# PIC32MX470F512L register map
Registers are 32-bit, access not given, reset 0x0 unless marked. A register's access mark holds for its fields unless they carry their own. Offsets are from the block's base; [hi:lo] are bit positions; {n}, {i} and the like mark numbered series; 'fields as' and 'values as' point back to an identical list.

## PORTG — PORTG peripheral
Base 0xBF886600
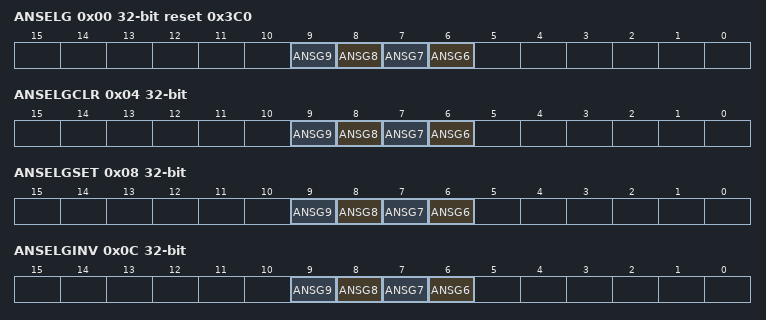
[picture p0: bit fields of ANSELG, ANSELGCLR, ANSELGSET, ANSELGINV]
0x00 ANSELG reset 0x3C0
  [n] ANSG{n} (n=6..9)
0x04 ANSELGCLR
  [n] ANSG{n} (n=6..9)
0x08 ANSELGSET
  [n] ANSG{n} (n=6..9)
0x0C ANSELGINV
  [n] ANSG{n} (n=6..9)
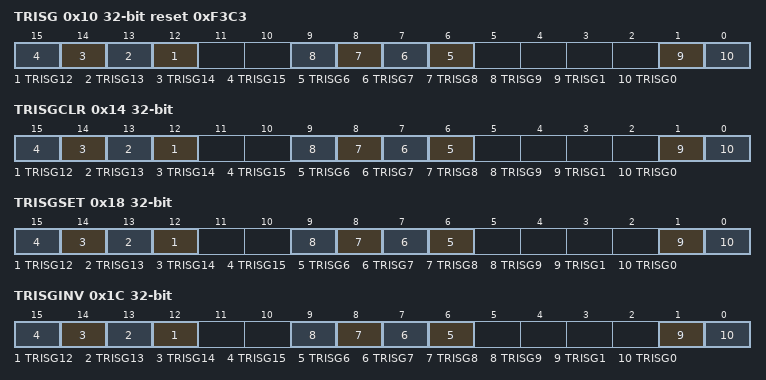
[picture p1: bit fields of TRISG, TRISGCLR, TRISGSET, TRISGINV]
0x10 TRISG reset 0xF3C3
  [n] TRISG{n} (n=12..15), [n] TRISG{n} (n=6..9), [1] TRISG1, [0] TRISG0
0x14 TRISGCLR
  fields as TRISG
0x18 TRISGSET
  fields as TRISG
0x1C TRISGINV
  fields as TRISG
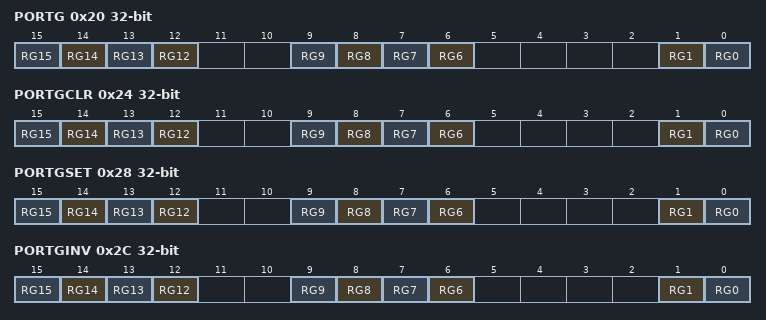
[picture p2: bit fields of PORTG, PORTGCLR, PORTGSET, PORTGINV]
0x20 PORTG
  [n] RG{n} (n=12..15), [n] RG{n} (n=6..9), [1] RG1, [0] RG0
0x24 PORTGCLR
  [n] RG{n} (n=12..15), [n] RG{n} (n=6..9), [1] RG1, [0] RG0
0x28 PORTGSET
  [n] RG{n} (n=12..15), [n] RG{n} (n=6..9), [1] RG1, [0] RG0
0x2C PORTGINV
  [n] RG{n} (n=12..15), [n] RG{n} (n=6..9), [1] RG1, [0] RG0
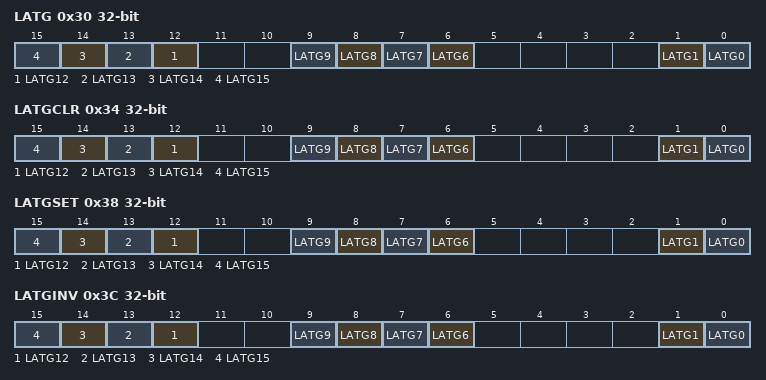
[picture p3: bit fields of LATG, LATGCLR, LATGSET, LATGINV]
0x30 LATG
  [n] LATG{n} (n=12..15), [n] LATG{n} (n=6..9), [1] LATG1, [0] LATG0
0x34 LATGCLR
  [n] LATG{n} (n=12..15), [n] LATG{n} (n=6..9), [1] LATG1, [0] LATG0
0x38 LATGSET
  [n] LATG{n} (n=12..15), [n] LATG{n} (n=6..9), [1] LATG1, [0] LATG0
0x3C LATGINV
  [n] LATG{n} (n=12..15), [n] LATG{n} (n=6..9), [1] LATG1, [0] LATG0
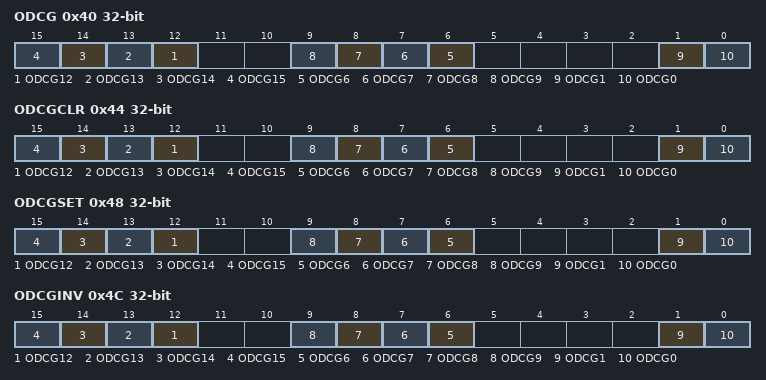
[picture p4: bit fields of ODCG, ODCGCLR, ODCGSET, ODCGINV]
0x40 ODCG
  [n] ODCG{n} (n=12..15), [n] ODCG{n} (n=6..9), [1] ODCG1, [0] ODCG0
0x44 ODCGCLR
  [n] ODCG{n} (n=12..15), [n] ODCG{n} (n=6..9), [1] ODCG1, [0] ODCG0
0x48 ODCGSET
  [n] ODCG{n} (n=12..15), [n] ODCG{n} (n=6..9), [1] ODCG1, [0] ODCG0
0x4C ODCGINV
  [n] ODCG{n} (n=12..15), [n] ODCG{n} (n=6..9), [1] ODCG1, [0] ODCG0
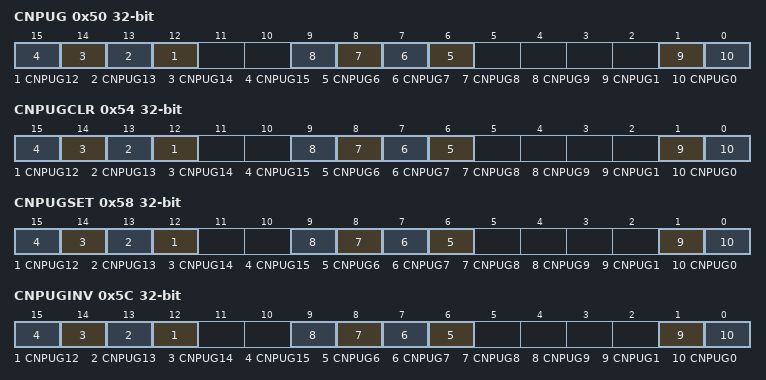
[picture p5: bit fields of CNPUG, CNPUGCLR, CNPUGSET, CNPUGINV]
0x50 CNPUG
  [n] CNPUG{n} (n=12..15), [n] CNPUG{n} (n=6..9), [1] CNPUG1, [0] CNPUG0
0x54 CNPUGCLR
  fields as CNPUG
0x58 CNPUGSET
  fields as CNPUG
0x5C CNPUGINV
  fields as CNPUG
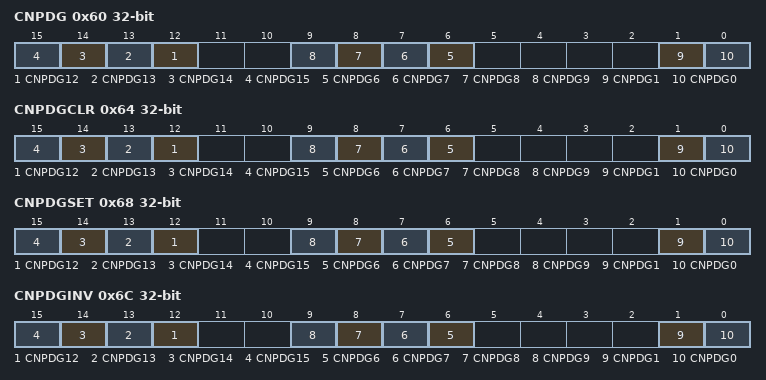
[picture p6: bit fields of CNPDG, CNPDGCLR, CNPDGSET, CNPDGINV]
0x60 CNPDG
  [n] CNPDG{n} (n=12..15), [n] CNPDG{n} (n=6..9), [1] CNPDG1, [0] CNPDG0
0x64 CNPDGCLR
  fields as CNPDG
0x68 CNPDGSET
  fields as CNPDG
0x6C CNPDGINV
  fields as CNPDG
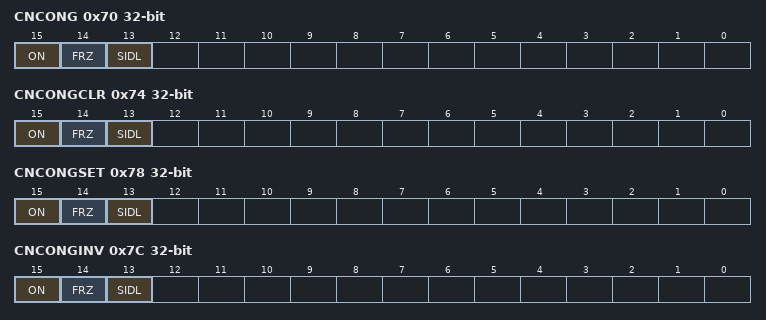
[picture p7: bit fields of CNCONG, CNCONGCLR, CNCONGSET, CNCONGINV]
0x70 CNCONG
  [15] ON, [14] FRZ, [13] SIDL
0x74 CNCONGCLR
  [15] ON, [14] FRZ, [13] SIDL
0x78 CNCONGSET
  [15] ON, [14] FRZ, [13] SIDL
0x7C CNCONGINV
  [15] ON, [14] FRZ, [13] SIDL
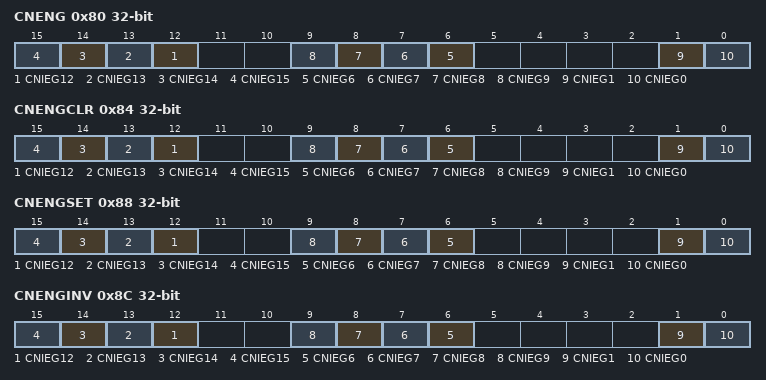
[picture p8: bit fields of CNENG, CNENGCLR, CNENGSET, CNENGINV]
0x80 CNENG
  [n] CNIEG{n} (n=12..15), [n] CNIEG{n} (n=6..9), [1] CNIEG1, [0] CNIEG0
0x84 CNENGCLR
  fields as CNENG
0x88 CNENGSET
  fields as CNENG
0x8C CNENGINV
  fields as CNENG
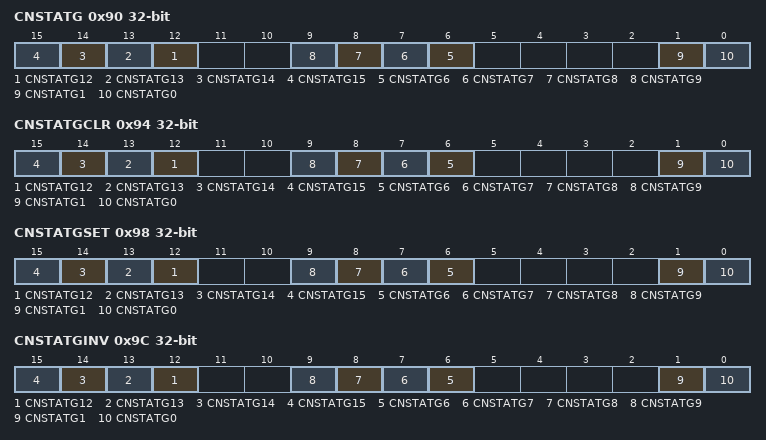
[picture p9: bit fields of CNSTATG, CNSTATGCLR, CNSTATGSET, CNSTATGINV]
0x90 CNSTATG
  [n] CNSTATG{n} (n=12..15), [n] CNSTATG{n} (n=6..9), [1] CNSTATG1, [0] CNSTATG0
0x94 CNSTATGCLR
  fields as CNSTATG
0x98 CNSTATGSET
  fields as CNSTATG
0x9C CNSTATGINV
  fields as CNSTATG

## WDT — WDT peripheral
Base 0xBF800000
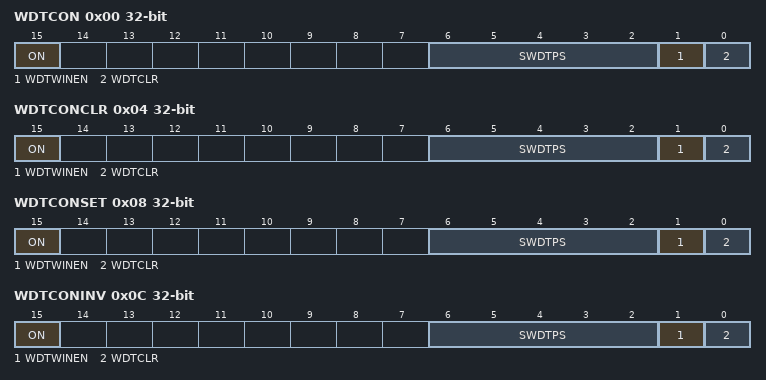
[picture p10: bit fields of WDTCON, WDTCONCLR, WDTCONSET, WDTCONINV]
0x00 WDTCON
  [15] ON, [6:2] SWDTPS, [1] WDTWINEN, [0] WDTCLR
0x04 WDTCONCLR
  [15] ON, [6:2] SWDTPS, [1] WDTWINEN, [0] WDTCLR
0x08 WDTCONSET
  [15] ON, [6:2] SWDTPS, [1] WDTWINEN, [0] WDTCLR
0x0C WDTCONINV
  [15] ON, [6:2] SWDTPS, [1] WDTWINEN, [0] WDTCLR

## RTCC — RTCC peripheral
Base 0xBF800200
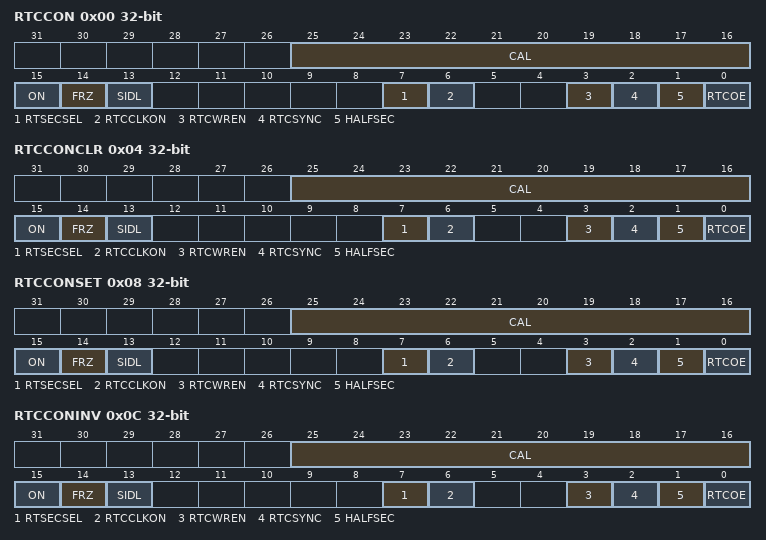
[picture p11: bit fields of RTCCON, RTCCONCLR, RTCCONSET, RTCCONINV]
0x00 RTCCON
  [25:16] CAL, [15] ON, [14] FRZ, [13] SIDL, [7] RTSECSEL, [6] RTCCLKON, [3] RTCWREN, [2] RTCSYNC, [1] HALFSEC, [0] RTCOE
0x04 RTCCONCLR
  fields as RTCCON
0x08 RTCCONSET
  fields as RTCCON
0x0C RTCCONINV
  fields as RTCCON
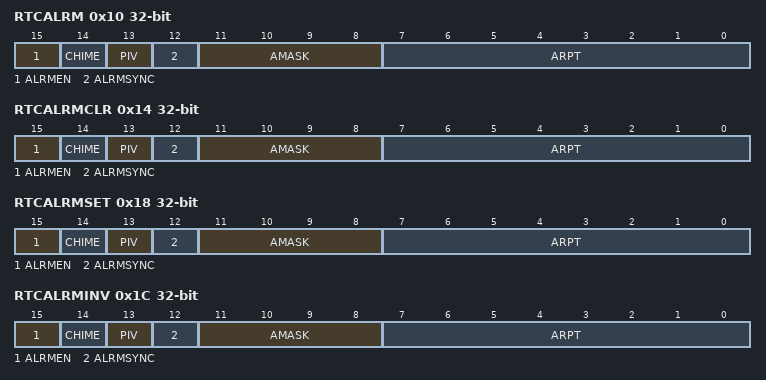
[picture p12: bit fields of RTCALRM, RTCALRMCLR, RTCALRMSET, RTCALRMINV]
0x10 RTCALRM
  [15] ALRMEN, [14] CHIME, [13] PIV, [12] ALRMSYNC, [11:8] AMASK, [7:0] ARPT
0x14 RTCALRMCLR
  fields as RTCALRM
0x18 RTCALRMSET
  fields as RTCALRM
0x1C RTCALRMINV
  fields as RTCALRM
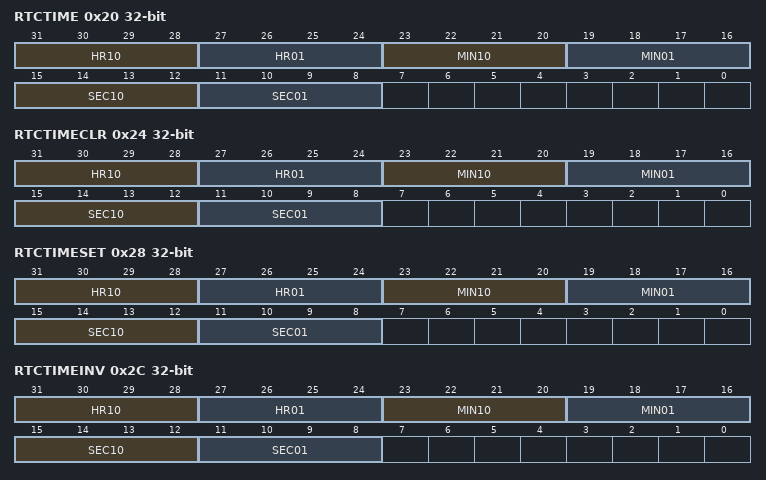
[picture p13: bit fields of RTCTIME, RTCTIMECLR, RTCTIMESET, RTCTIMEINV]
0x20 RTCTIME
  [31:28] HR10, [27:24] HR01, [23:20] MIN10, [19:16] MIN01, [15:12] SEC10, [11:8] SEC01
0x24 RTCTIMECLR
  fields as RTCTIME
0x28 RTCTIMESET
  fields as RTCTIME
0x2C RTCTIMEINV
  fields as RTCTIME
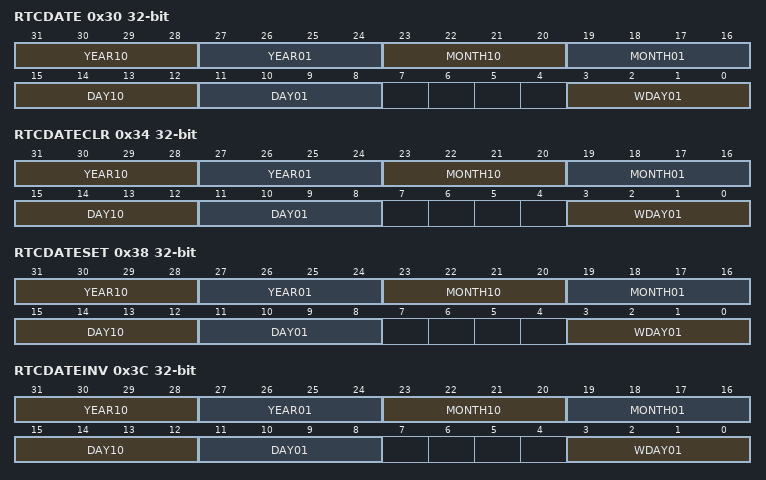
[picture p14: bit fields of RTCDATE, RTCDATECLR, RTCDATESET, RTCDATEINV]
0x30 RTCDATE
  [31:28] YEAR10, [27:24] YEAR01, [23:20] MONTH10, [19:16] MONTH01, [15:12] DAY10, [11:8] DAY01, [3:0] WDAY01
0x34 RTCDATECLR
  fields as RTCDATE
0x38 RTCDATESET
  fields as RTCDATE
0x3C RTCDATEINV
  fields as RTCDATE
0x40 ALRMTIME
  fields as RTCTIME
0x44 ALRMTIMECLR
  fields as RTCTIME
0x48 ALRMTIMESET
  fields as RTCTIME
0x4C ALRMTIMEINV
  fields as RTCTIME
0x50 ALRMDATE
  [23:20] MONTH10, [19:16] MONTH01, [15:12] DAY10, [11:8] DAY01, [3:0] WDAY01
0x54 ALRMDATECLR
  fields as ALRMDATE
0x58 ALRMDATESET
  fields as ALRMDATE
0x5C ALRMDATEINV
  fields as ALRMDATE
